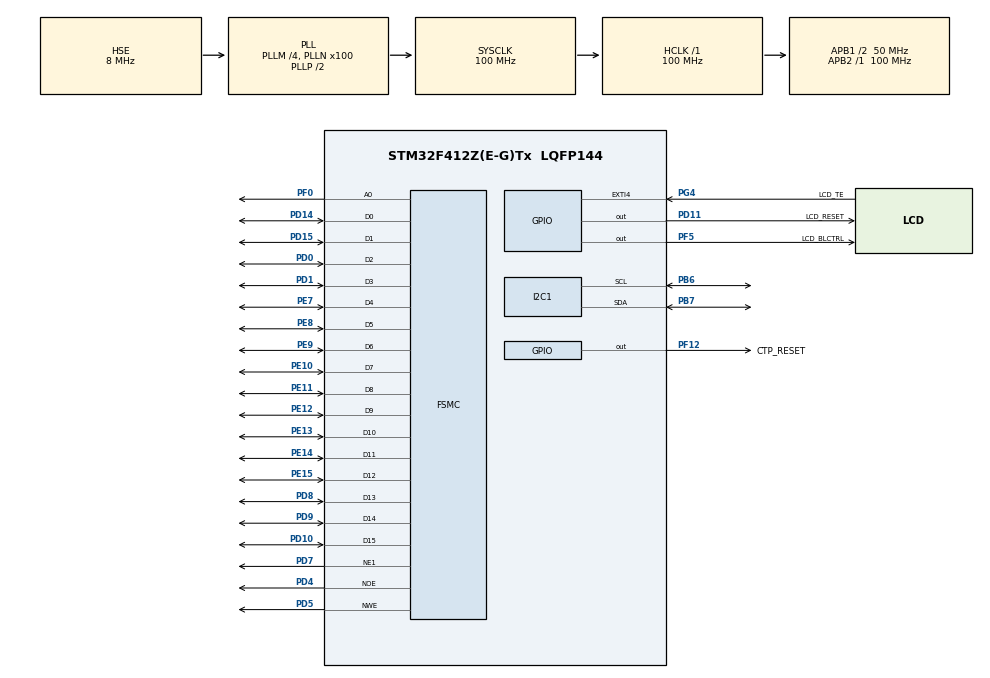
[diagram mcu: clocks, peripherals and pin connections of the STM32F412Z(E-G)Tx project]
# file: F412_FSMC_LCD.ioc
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FSMC.AddressSetupTime1=3
FSMC.BusTurnAroundDuration1=2
FSMC.DataSetupTime1=2
Mcu.Family=STM32F4
Mcu.Name=STM32F412Z(E-G)Tx
Mcu.Package=LQFP144
NVIC.PriorityGroup=NVIC_PRIORITYGROUP_4
PA13.Mode=Serial_Wire
PA13.Signal=SYS_JTMS-SWDIO
PA14.Mode=Serial_Wire
PA14.Signal=SYS_JTCK-SWCLK
PB6.Mode=I2C
PB6.Signal=I2C1_SCL
PB7.Mode=I2C
PB7.Signal=I2C1_SDA
PD0.Signal=FSMC_D2_DA2
PD1.Signal=FSMC_D3_DA3
PD10.Signal=FSMC_D15_DA15
PD11.GPIO_Label=LCD_RESET
PD11.Signal=GPIO_Output
PD14.Signal=FSMC_D0_DA0
PD15.Signal=FSMC_D1_DA1
PD4.Signal=FSMC_NOE
PD5.Signal=FSMC_NWE
PD7.Mode=NorPsramChipSelect1_1
PD7.Signal=FSMC_NE1
PD8.Signal=FSMC_D13_DA13
PD9.Signal=FSMC_D14_DA14
PE10.Signal=FSMC_D7_DA7
PE11.Signal=FSMC_D8_DA8
PE12.Signal=FSMC_D9_DA9
PE13.Signal=FSMC_D10_DA10
PE14.Signal=FSMC_D11_DA11
PE15.Signal=FSMC_D12_DA12
PE7.Signal=FSMC_D4_DA4
PE8.Signal=FSMC_D5_DA5
PE9.Signal=FSMC_D6_DA6
PF0.Signal=FSMC_A0
PF12.GPIO_Label=CTP_RESET
PF12.Signal=GPIO_Output
PF5.GPIO_Label=LCD_BLCTRL
PF5.PinState=GPIO_PIN_SET
PF5.Signal=GPIO_Output
PG4.GPIO_Label=LCD_TE
PG4.Signal=GPXTI4
PH0\ -\ OSC_IN.Mode=HSE-External-Oscillator
PH0\ -\ OSC_IN.Signal=RCC_OSC_IN
PH1\ -\ OSC_OUT.Mode=HSE-External-Oscillator
PH1\ -\ OSC_OUT.Signal=RCC_OSC_OUT
ProjectManager.HeapSize=0x200
ProjectManager.StackSize=0x400
ProjectManager.TargetToolchain=STM32CubeIDE
RCC.48MHZClocksFreq_Value=48000000
RCC.AHBFreq_Value=100000000
RCC.APB1CLKDivider=RCC_HCLK_DIV2
RCC.APB1Freq_Value=50000000
RCC.APB1TimFreq_Value=100000000
RCC.APB2Freq_Value=100000000
RCC.APB2TimFreq_Value=100000000
RCC.CortexFreq_Value=100000000
RCC.HCLKFreq_Value=100000000
RCC.HSE_VALUE=8000000
RCC.HSI_VALUE=16000000
RCC.PLLI2SM=4
RCC.PLLI2SN=50
RCC.PLLM=4
RCC.PLLN=100
RCC.PLLQ=3
RCC.PLLSourceVirtual=RCC_PLLSOURCE_HSE
RCC.SYSCLKFreq_VALUE=100000000
RCC.SYSCLKSource=RCC_SYSCLKSOURCE_PLLCLK
RCC.USBFreq_Value=66666666.666666664
RCC.VCOOutputFreq_Value=200000000
SH.FSMC_A0.0=FSMC_A0,A0_1
SH.FSMC_D0_DA0.0=FSMC_D0,16b-d1
SH.FSMC_D10_DA10.0=FSMC_D10,16b-d1
SH.FSMC_D11_DA11.0=FSMC_D11,16b-d1
SH.FSMC_D12_DA12.0=FSMC_D12,16b-d1
SH.FSMC_D13_DA13.0=FSMC_D13,16b-d1
SH.FSMC_D14_DA14.0=FSMC_D14,16b-d1
SH.FSMC_D15_DA15.0=FSMC_D15,16b-d1
SH.FSMC_D1_DA1.0=FSMC_D1,16b-d1
SH.FSMC_D2_DA2.0=FSMC_D2,16b-d1
SH.FSMC_D3_DA3.0=FSMC_D3,16b-d1
SH.FSMC_D4_DA4.0=FSMC_D4,16b-d1
SH.FSMC_D5_DA5.0=FSMC_D5,16b-d1
SH.FSMC_D6_DA6.0=FSMC_D6,16b-d1
SH.FSMC_D7_DA7.0=FSMC_D7,16b-d1
SH.FSMC_D8_DA8.0=FSMC_D8,16b-d1
SH.FSMC_D9_DA9.0=FSMC_D9,16b-d1
SH.FSMC_NOE.0=FSMC_NOE,Lcd1
SH.FSMC_NWE.0=FSMC_NWE,Lcd1
board=STM32F412G-DISCO

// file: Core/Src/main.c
/* USER CODE BEGIN Header */
/**
 ******************************************************************************
 * @file           : main.c
 * @brief          : Main program body
 ******************************************************************************
 * @attention
 *
 * Copyright (c) 2024 STMicroelectronics.
 * All rights reserved.
 *
 * This software is licensed under terms that can be found in the LICENSE file
 * in the root directory of this software component.
 * If no LICENSE file comes with this software, it is provided AS-IS.
 *
 ******************************************************************************
 */
/* USER CODE END Header */
#include "main.h"

/* USER CODE BEGIN Includes */
#include "lvgl.h"
#include "LCD_Controller.h"
#include "LCD_Touch.h"
#include "ui.h"
/* USER CODE END Includes */

I2C_HandleTypeDef hi2c1;

SRAM_HandleTypeDef hsram1;

void SystemClock_Config(void);
static void MX_GPIO_Init(void);
static void MX_FSMC_Init(void);
static void MX_I2C1_Init(void);

int main(void)
{

	/* MCU Configuration--------------------------------------------------------*/

	/* Reset of all peripherals, Initializes the Flash interface and the Systick. */
	HAL_Init();

	/* Configure the system clock */
	SystemClock_Config();

	/* Initialize all configured peripherals */
	MX_GPIO_Init();
	MX_FSMC_Init();
	MX_I2C1_Init();
	/* USER CODE BEGIN 2 */

	lv_init ();
	lv_port_disp_init();
	lv_port_indev_init();
	ui_init();

	/* USER CODE END 2 */

	/* Infinite loop */
	/* USER CODE BEGIN WHILE */
	while (1)
	{
		lv_timer_handler();
		HAL_Delay(5);
	}
	/* USER CODE END 3 */
}

void SystemClock_Config(void)
{
	RCC_OscInitTypeDef RCC_OscInitStruct = {0};
	RCC_ClkInitTypeDef RCC_ClkInitStruct = {0};

	/** Configure the main internal regulator output voltage
	 */
	__HAL_RCC_PWR_CLK_ENABLE();
	__HAL_PWR_VOLTAGESCALING_CONFIG(PWR_REGULATOR_VOLTAGE_SCALE1);

	/** Initializes the RCC Oscillators according to the specified parameters
	 * in the RCC_OscInitTypeDef structure.
	 */
	RCC_OscInitStruct.OscillatorType = RCC_OSCILLATORTYPE_HSE;
	RCC_OscInitStruct.HSEState = RCC_HSE_ON;
	RCC_OscInitStruct.PLL.PLLState = RCC_PLL_ON;
	RCC_OscInitStruct.PLL.PLLSource = RCC_PLLSOURCE_HSE;
	RCC_OscInitStruct.PLL.PLLM = 4;
	RCC_OscInitStruct.PLL.PLLN = 100;
	RCC_OscInitStruct.PLL.PLLP = RCC_PLLP_DIV2;
	RCC_OscInitStruct.PLL.PLLQ = 3;
	RCC_OscInitStruct.PLL.PLLR = 2;
	if (HAL_RCC_OscConfig(&RCC_OscInitStruct) != HAL_OK)
	{
		Error_Handler();
	}

	/** Initializes the CPU, AHB and APB buses clocks
	 */
	RCC_ClkInitStruct.ClockType = RCC_CLOCKTYPE_HCLK|RCC_CLOCKTYPE_SYSCLK
			|RCC_CLOCKTYPE_PCLK1|RCC_CLOCKTYPE_PCLK2;
	RCC_ClkInitStruct.SYSCLKSource = RCC_SYSCLKSOURCE_PLLCLK;
	RCC_ClkInitStruct.AHBCLKDivider = RCC_SYSCLK_DIV1;
	RCC_ClkInitStruct.APB1CLKDivider = RCC_HCLK_DIV2;
	RCC_ClkInitStruct.APB2CLKDivider = RCC_HCLK_DIV1;

	if (HAL_RCC_ClockConfig(&RCC_ClkInitStruct, FLASH_LATENCY_3) != HAL_OK)
	{
		Error_Handler();
	}
}

static void MX_I2C1_Init(void)
{

	hi2c1.Instance = I2C1;
	hi2c1.Init.ClockSpeed = 100000;
	hi2c1.Init.DutyCycle = I2C_DUTYCYCLE_2;
	hi2c1.Init.OwnAddress1 = 0;
	hi2c1.Init.AddressingMode = I2C_ADDRESSINGMODE_7BIT;
	hi2c1.Init.DualAddressMode = I2C_DUALADDRESS_DISABLE;
	hi2c1.Init.OwnAddress2 = 0;
	hi2c1.Init.GeneralCallMode = I2C_GENERALCALL_DISABLE;
	hi2c1.Init.NoStretchMode = I2C_NOSTRETCH_DISABLE;
	if (HAL_I2C_Init(&hi2c1) != HAL_OK)
	{
		Error_Handler();
	}

}

static void MX_GPIO_Init(void)
{
	GPIO_InitTypeDef GPIO_InitStruct = {0};

	/* GPIO Ports Clock Enable */
	__HAL_RCC_GPIOF_CLK_ENABLE();
	__HAL_RCC_GPIOH_CLK_ENABLE();
	__HAL_RCC_GPIOE_CLK_ENABLE();
	__HAL_RCC_GPIOD_CLK_ENABLE();
	__HAL_RCC_GPIOG_CLK_ENABLE();
	__HAL_RCC_GPIOA_CLK_ENABLE();
	__HAL_RCC_GPIOB_CLK_ENABLE();

	/*Configure GPIO pin Output Level */
	HAL_GPIO_WritePin(LCD_BLCTRL_GPIO_Port, LCD_BLCTRL_Pin, GPIO_PIN_SET);

	/*Configure GPIO pin Output Level */
	HAL_GPIO_WritePin(CTP_RESET_GPIO_Port, CTP_RESET_Pin, GPIO_PIN_RESET);

	/*Configure GPIO pin Output Level */
	HAL_GPIO_WritePin(LCD_RESET_GPIO_Port, LCD_RESET_Pin, GPIO_PIN_RESET);

	/*Configure GPIO pins : LCD_BLCTRL_Pin CTP_RESET_Pin */
	GPIO_InitStruct.Pin = LCD_BLCTRL_Pin|CTP_RESET_Pin;
	GPIO_InitStruct.Mode = GPIO_MODE_OUTPUT_PP;
	GPIO_InitStruct.Pull = GPIO_NOPULL;
	GPIO_InitStruct.Speed = GPIO_SPEED_FREQ_LOW;
	HAL_GPIO_Init(GPIOF, &GPIO_InitStruct);

	/*Configure GPIO pin : LCD_RESET_Pin */
	GPIO_InitStruct.Pin = LCD_RESET_Pin;
	GPIO_InitStruct.Mode = GPIO_MODE_OUTPUT_PP;
	GPIO_InitStruct.Pull = GPIO_NOPULL;
	GPIO_InitStruct.Speed = GPIO_SPEED_FREQ_LOW;
	HAL_GPIO_Init(LCD_RESET_GPIO_Port, &GPIO_InitStruct);

	/*Configure GPIO pin : LCD_TE_Pin */
	GPIO_InitStruct.Pin = LCD_TE_Pin;
	GPIO_InitStruct.Mode = GPIO_MODE_IT_RISING;
	GPIO_InitStruct.Pull = GPIO_NOPULL;
	HAL_GPIO_Init(LCD_TE_GPIO_Port, &GPIO_InitStruct);

}

/* FSMC initialization function */
static void MX_FSMC_Init(void)
{

	FSMC_NORSRAM_TimingTypeDef Timing = {0};

	/** Perform the SRAM1 memory initialization sequence
	 */
	hsram1.Instance = FSMC_NORSRAM_DEVICE;
	hsram1.Extended = FSMC_NORSRAM_EXTENDED_DEVICE;
	/* hsram1.Init */
	hsram1.Init.NSBank = FSMC_NORSRAM_BANK1;
	hsram1.Init.DataAddressMux = FSMC_DATA_ADDRESS_MUX_DISABLE;
	hsram1.Init.MemoryType = FSMC_MEMORY_TYPE_SRAM;
	hsram1.Init.MemoryDataWidth = FSMC_NORSRAM_MEM_BUS_WIDTH_16;
	hsram1.Init.BurstAccessMode = FSMC_BURST_ACCESS_MODE_DISABLE;
	hsram1.Init.WaitSignalPolarity = FSMC_WAIT_SIGNAL_POLARITY_LOW;
	hsram1.Init.WaitSignalActive = FSMC_WAIT_TIMING_BEFORE_WS;
	hsram1.Init.WriteOperation = FSMC_WRITE_OPERATION_ENABLE;
	hsram1.Init.WaitSignal = FSMC_WAIT_SIGNAL_DISABLE;
	hsram1.Init.ExtendedMode = FSMC_EXTENDED_MODE_DISABLE;
	hsram1.Init.AsynchronousWait = FSMC_ASYNCHRONOUS_WAIT_DISABLE;
	hsram1.Init.WriteBurst = FSMC_WRITE_BURST_DISABLE;
	hsram1.Init.ContinuousClock = FSMC_CONTINUOUS_CLOCK_SYNC_ONLY;
	hsram1.Init.WriteFifo = FSMC_WRITE_FIFO_ENABLE;
	hsram1.Init.PageSize = FSMC_PAGE_SIZE_NONE;
	/* Timing */
	Timing.AddressSetupTime = 3;
	Timing.AddressHoldTime = 15;
	Timing.DataSetupTime = 2;
	Timing.BusTurnAroundDuration = 2;
	Timing.CLKDivision = 16;
	Timing.DataLatency = 17;
	Timing.AccessMode = FSMC_ACCESS_MODE_A;
	/* ExtTiming */

	if (HAL_SRAM_Init(&hsram1, &Timing, NULL) != HAL_OK)
	{
		Error_Handler( );
	}

}

void Error_Handler(void)
{
	__disable_irq();
	while (1)
	{
	}
}
